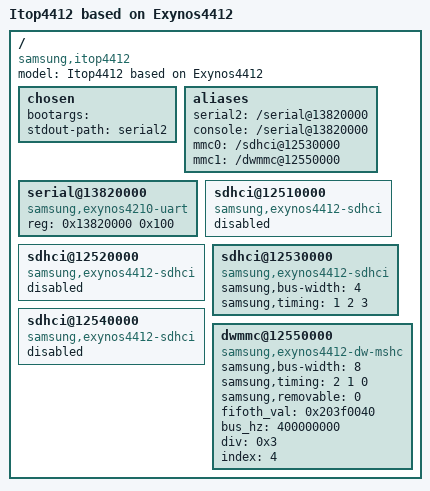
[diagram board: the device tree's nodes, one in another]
// SPDX-License-Identifier: GPL-2.0+
/*
 * Itop4412 board device tree source
 *
 * Copyright (c) 2014 Samsung Electronics Co., Ltd.
 *		http://www.samsung.com
 */

/dts-v1/;
#include "exynos4412.dtsi"

/ {
	model = "Itop4412 based on Exynos4412";
	compatible = "samsung,itop4412", "samsung,exynos4412";
	
	chosen {
		bootargs = "";
		stdout-path = "serial2";
	};
	
	aliases {
		serial2 = "/serial@13820000";
		console = "/serial@13820000";
		mmc0 = "/sdhci@12530000";
		mmc1 = "/dwmmc@12550000";
	};

	serial@13820000 {
		compatible = "samsung,exynos4210-uart";
		reg = <0x13820000 0x100>;
		status = "okay";
	};
	
	sdhci@12510000 {
		compatible = "samsung,exynos4412-sdhci";
		status = "disabled";
	};
	
	sdhci@12520000 {
		compatible = "samsung,exynos4412-sdhci";
		status = "disabled";
	};
	
	sdhci@12530000 {
		compatible = "samsung,exynos4412-sdhci";
		samsung,bus-width = <4>;
		samsung,timing = <1 2 3>;
		status = "okay";
	};
	
	sdhci@12540000 {
		compatible = "samsung,exynos4412-sdhci";
		status = "disabled";
	};
	
	dwmmc@12550000 {
		compatible = "samsung,exynos4412-dw-mshc";
		samsung,bus-width = <8>;
		samsung,timing = <2 1 0>;
		samsung,removable = <0>;
		fifoth_val = <0x203f0040>;
		bus_hz = <400000000>;
		div = <0x3>;
		index = <4>;
		status = "okay";
	};
};
